VERSION ""

NS_ :

BS_:

BU_: Tester ECM BCM ACC ICM
VAL_TABLE_ cruiseswreq 7 "None" 6 "Time Gap -" 5 "Time gap +" 4 "Resume" 3 "Coast" 2 "Set/ Accel" 1 "ON" 0 "OFF" ;
VAL_TABLE_ BrakeState 1 "Applied" 0 "Not Applied" ;
VAL_TABLE_ Brakedecelreq 1 "Apply" 0 "Do Not Apply" ;
VAL_TABLE_ vtdriverinfo 5 "ACC fault" 4 "ACC DriverIntervention required" 3 "ACC Active" 2 "ACC Standby" 1 "ACC ON" 0 "ACC OFF" ;

BO_ 1282 ECM_NM: 2 ECM

BO_ 1283 ICM_NM: 8 ICM

BO_ 1284 Acc_NM: 2 ACC

BO_ 1281 BCM_NM: 2 BCM

BO_ 1576 DiagRsp: 8 ACC
 SG_ DiagRsp : 0|64@1+ (1,0) [0|0] ""  Tester

BO_ 1568 Diagrequest: 8 Tester
 SG_ DiagRequest : 0|64@1+ (1,0) [0|0] ""  ACC

BO_ 288 BCMInfo: 8 BCM
 SG_ VehicleSpeed : 0|8@1+ (1,0) [0|0] ""  ECM,ACC

BO_ 560 ECMInfo: 8 ECM
 SG_ BrakeSwitch2 : 0|1@1+ (1,0) [0|0] ""  ACC

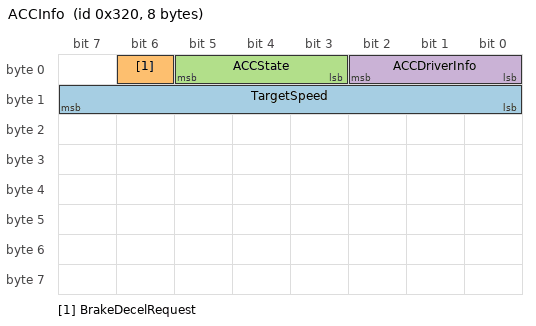
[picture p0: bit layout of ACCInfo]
BO_ 800 ACCInfo: 8 ACC
 SG_ TargetSpeed : 8|8@1+ (1,0) [0|0] ""  ECM
 SG_ BrakeDecelRequest : 6|1@1+ (1,0) [0|0] ""  BCM
 SG_ ACCState : 3|3@1+ (1,0) [0|0] ""  ECM,BCM
 SG_ ACCDriverInfo : 0|3@1+ (1,0) [0|0] ""  ICM

BO_ 529 ICM_Info: 8 ICM
 SG_ CruiseSwitchRequest : 1|3@1+ (1,0) [0|0] ""  ACC
 SG_ BrakeSwitch1 : 0|1@1+ (1,0) [0|0] ""  ACC

BA_DEF_ BO_  "NmMessage" ENUM  "NO","Yes";
BA_DEF_ BU_  "NmNode" ENUM  "No","Yes";
BA_DEF_ BU_  "NmStationAddress" HEX 0 0;
BA_DEF_  "NmBaseAddress" HEX 0 0;
BA_DEF_ BU_  "NodeLayerModules" STRING ;
BA_DEF_ BU_  "ILUsed" ENUM  "NO","YES";
BA_DEF_ BO_  "GenMsgCycleTime" INT 0 0;
BA_DEF_ BO_  "GenMsgSendType" ENUM  "Cyclic","Event","Event+Cyclic";
BA_DEF_ SG_  "GenSigStartValue" INT 0 0;
BA_DEF_  "BusType" STRING ;
BA_DEF_DEF_  "NmMessage" "NO";
BA_DEF_DEF_  "NmNode" "No";
BA_DEF_DEF_  "NmStationAddress" 0;
BA_DEF_DEF_  "NmBaseAddress" 1280;
BA_DEF_DEF_  "NodeLayerModules" "CANoeILNLVector.dll";
BA_DEF_DEF_  "ILUsed" "YES";
BA_DEF_DEF_  "GenMsgCycleTime" 50;
BA_DEF_DEF_  "GenMsgSendType" "Cyclic";
BA_DEF_DEF_  "GenSigStartValue" 0;
BA_DEF_DEF_  "BusType" "CAN";
BA_ "NodeLayerModules" BU_ Tester "CANoeILNLVector.dll,osek_tp.dll";
BA_ "NodeLayerModules" BU_ ECM "CANoeILNLVector.dll, OSEKNM01.dll";
BA_ "NmStationAddress" BU_ ECM 2;
BA_ "NmNode" BU_ ECM 1;
BA_ "NodeLayerModules" BU_ BCM "CANoeILNLVector.dll, OSEKNM01.dll";
BA_ "NmStationAddress" BU_ BCM 1;
BA_ "NmNode" BU_ BCM 1;
BA_ "NodeLayerModules" BU_ ACC "CANoeILNLVector.dll, osek_tp.dll, OSEKNM01.dll";
BA_ "NmStationAddress" BU_ ACC 4;
BA_ "NmNode" BU_ ACC 1;
BA_ "NodeLayerModules" BU_ ICM "CANoeILNLVector.dll, OSEKNM01.dll";
BA_ "NmStationAddress" BU_ ICM 3;
BA_ "NmNode" BU_ ICM 1;
BA_ "GenMsgCycleTime" BO_ 1282 0;
BA_ "GenMsgSendType" BO_ 1282 1;
BA_ "NmMessage" BO_ 1282 1;
BA_ "GenMsgCycleTime" BO_ 1283 0;
BA_ "GenMsgSendType" BO_ 1283 1;
BA_ "NmMessage" BO_ 1283 1;
BA_ "GenMsgCycleTime" BO_ 1284 0;
BA_ "GenMsgSendType" BO_ 1284 1;
BA_ "NmMessage" BO_ 1284 1;
BA_ "GenMsgCycleTime" BO_ 1281 0;
BA_ "GenMsgSendType" BO_ 1281 1;
BA_ "NmMessage" BO_ 1281 1;
BA_ "GenMsgSendType" BO_ 1576 1;
BA_ "GenMsgSendType" BO_ 1568 1;
BA_ "GenMsgCycleTime" BO_ 288 150;
BA_ "GenMsgCycleTime" BO_ 560 250;
BA_ "GenMsgCycleTime" BO_ 800 100;
BA_ "GenMsgCycleTime" BO_ 529 100;
BA_ "GenSigStartValue" SG_ 529 CruiseSwitchRequest 7;
VAL_ 560 BrakeSwitch2 1 "Applied" 0 "Not Applied" ;
VAL_ 800 BrakeDecelRequest 1 "Apply" 0 "Do Not Apply" ;
VAL_ 800 ACCState 5 "ACC fault" 4 "ACC DriverIntervention required" 3 "ACC Active" 2 "ACC Standby" 1 "ACC ON" 0 "ACC OFF" ;
VAL_ 800 ACCDriverInfo 5 "ACC fault" 4 "ACC DriverIntervention required" 3 "ACC Active" 2 "ACC Standby" 1 "ACC ON" 0 "ACC OFF" ;
VAL_ 529 CruiseSwitchRequest 7 "None" 6 "Time Gap -" 5 "Time gap +" 4 "Resume" 3 "Coast" 2 "Set/ Accel" 1 "ON" 0 "OFF" ;
VAL_ 529 BrakeSwitch1 1 "Applied" 0 "Not Applied" ;
